# MKL33Z4 register map
Vendor: Freescale Semiconductor, Inc.; Series: Kinetis_L; File version: 1.6
CPU: CM0PLUS r0p0, little endian, no MPU, no FPU, VTOR, 2 interrupt priority bits
Registers are 32-bit, read-write, reset 0x0 unless marked. A register's access mark holds for its fields unless they carry their own. Offsets are from the block's base; [hi:lo] are bit positions; {n}, {i} and the like mark numbered series; 'fields as' and 'values as' point back to an identical list.

## GPIOA — General Purpose Input/Output
Base 0x400FF000; register names take the prefix GPIOA_
0x00 PDOR — Port Data Output Register
  [31:0] PDO — Port Data Output
    0=Logic level 0 is driven on pin, provided pin is configured for general-purpose output; 1=Logic level 1 is driven on pin, provided pin is configured for general-purpose output
0x04 PSOR wo — Port Set Output Register
  [31:0] PTSO — Port Set Output
    0=Corresponding bit in PDORn does not change; 1=Corresponding bit in PDORn is set to logic 1
0x08 PCOR wo — Port Clear Output Register
  [31:0] PTCO — Port Clear Output
    0=Corresponding bit in PDORn does not change; 1=Corresponding bit in PDORn is cleared to logic 0
0x0C PTOR wo — Port Toggle Output Register
  [31:0] PTTO — Port Toggle Output
    0=Corresponding bit in PDORn does not change; 1=Corresponding bit in PDORn is set to the inverse of its existing logic state
0x10 PDIR ro — Port Data Input Register
  [31:0] PDI — Port Data Input
    0=Pin logic level is logic 0, or is not configured for use by digital function; 1=Pin logic level is logic 1
0x14 PDDR — Port Data Direction Register
  [31:0] PDD — Port Data Direction
    0=Pin is configured as general-purpose input, for the GPIO function; 1=Pin is configured as general-purpose output, for the GPIO function

## GPIOB — General Purpose Input/Output
Base 0x400FF040; register names take the prefix GPIOB_
Registers as GPIOA.

## GPIOC — General Purpose Input/Output
Base 0x400FF080; register names take the prefix GPIOC_
Registers as GPIOA.

## GPIOD — General Purpose Input/Output
Base 0x400FF0C0; register names take the prefix GPIOD_
Registers as GPIOA.

## GPIOE — General Purpose Input/Output
Base 0x400FF100; register names take the prefix GPIOE_
Registers as GPIOA.

## MTB — Micro Trace Buffer
Base 0xF0000000; register names take the prefix MTB_
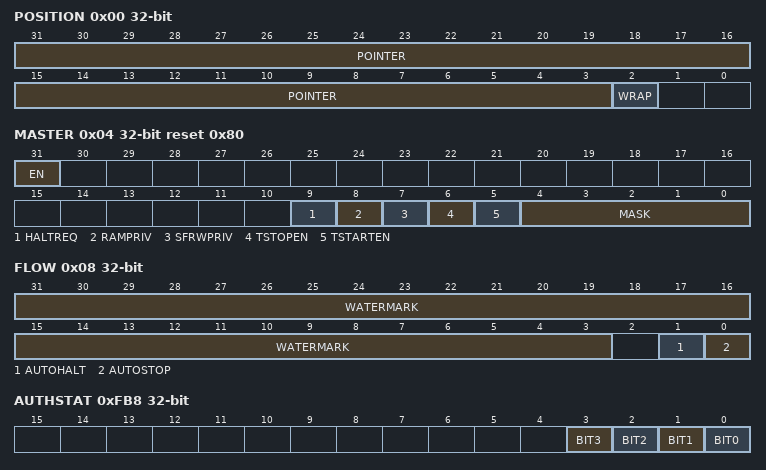
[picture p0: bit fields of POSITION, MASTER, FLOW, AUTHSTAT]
0x00 POSITION (reset mask 0x3) — MTB Position Register
  [31:3] POINTER — Trace Packet Address Pointer[28:0]
  [2] WRAP
0x04 MASTER reset 0x80 (reset mask 0xFFFFFFE0) — MTB Master Register
  [31] EN — Main Trace Enable
  [9] HALTREQ — Halt Request
  [8] RAMPRIV — RAM Privilege
  [7] SFRWPRIV — Special Function Register Write Privilege
  [6] TSTOPEN — Trace Stop Input Enable
  [5] TSTARTEN — Trace Start Input Enable
  [4:0] MASK
0x08 FLOW (reset mask 0x4) — MTB Flow Register
  [31:3] WATERMARK — WATERMARK[28:0]
  [1] AUTOHALT
  [0] AUTOSTOP
0x0C BASE ro reset not defined — MTB Base Register
  [31:0] BASEADDR
0xF00 MODECTRL ro — Integration Mode Control Register
0xFA0 TAGSET ro — Claim TAG Set Register
0xFA4 TAGCLEAR ro — Claim TAG Clear Register
0xFB0 LOCKACCESS ro
  [31:0] LOCKACCESS — Hardwired to 0x0000_0000
0xFB4 LOCKSTAT ro — Lock Status Register
0xFB8 AUTHSTAT ro — Authentication Status Register
  [3] BIT3
  [2] BIT2
  [1] BIT1
  [0] BIT0 — Connected to DBGEN.
0xFBC DEVICEARCH ro reset 0x47700A31 — Device Architecture Register
0xFC8 DEVICECFG ro — Device Configuration Register
0xFCC DEVICETYPID ro reset 0x31 — Device Type Identifier Register
0xFD0 PERIPHID{x} (x=4,5,6,7,0,1,2,3; step 0x4) ro reset not defined — Peripheral ID Register
  [31:0] PERIPHID
{0xFF0+4i} COMPID{i} (i=0..3) ro reset not defined — Component ID Register
  [31:0] COMPID — Component ID

## MTBDWT — MTB data watchpoint and trace
Base 0xF0001000; register names take the prefix MTBDWT_
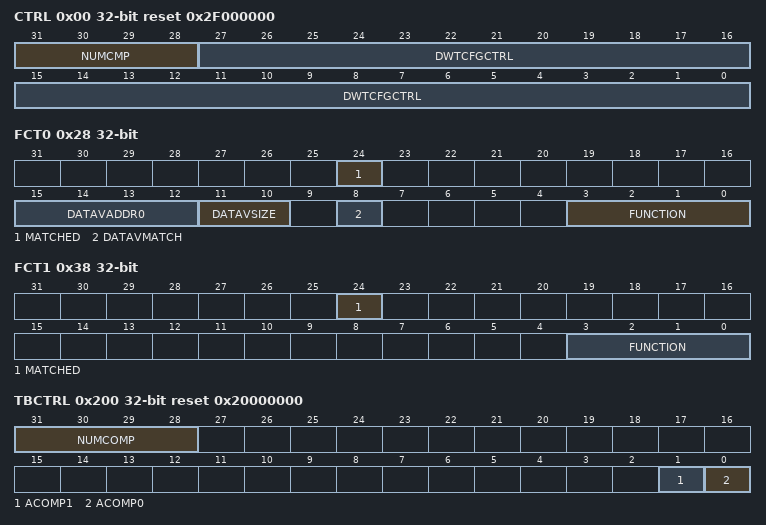
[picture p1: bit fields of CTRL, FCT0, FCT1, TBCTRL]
0x00 CTRL ro reset 0x2F000000 — MTB DWT Control Register
  [31:28] NUMCMP — Number of comparators
  [27:0] DWTCFGCTRL — DWT configuration controls
{0x20+0x10*i} COMP{i} (i=0..1) — MTB_DWT Comparator Register
  [31:0] COMP — Reference value for comparison
{0x24+0x10*i} MASK{i} (i=0..1) — MTB_DWT Comparator Mask Register
  [4:0] MASK
0x28 FCT0 — MTB_DWT Comparator Function Register 0
  [24] MATCHED ro — Comparator match
    0=No match; 1=Match occurred
  [15:12] DATAVADDR0 — Data Value Address 0
  [11:10] DATAVSIZE — Data Value Size
    0=Byte; 1=Halfword; 2=Word; 3=Reserved. Any attempts to use this value results in UNPREDICTABLE behavior.
  [8] DATAVMATCH — Data Value Match
    0=Perform address comparison; 1=Perform data value comparison
  [3:0] FUNCTION
    0=Disabled; 4=Instruction fetch; 5=Data operand read; 6=Data operand write; 7=Data operand (read + write)
0x38 FCT1 — MTB_DWT Comparator Function Register 1
  [24] MATCHED ro — Comparator match
    0=No match; 1=Match occurred
  [3:0] FUNCTION
    values as FCT0.FUNCTION
0x200 TBCTRL reset 0x20000000 — MTB_DWT Trace Buffer Control Register
  [31:28] NUMCOMP ro — Number of Comparators
  [1] ACOMP1 — Action based on Comparator 1 match
    0=Trigger TSTOP based on the assertion of MTBDWT_FCT1[MATCHED]; 1=Trigger TSTART based on the assertion of MTBDWT_FCT1[MATCHED]
  [0] ACOMP0 — Action based on Comparator 0 match
    0=Trigger TSTOP based on the assertion of MTBDWT_FCT0[MATCHED]; 1=Trigger TSTART based on the assertion of MTBDWT_FCT0[MATCHED]
0xFC8 DEVICECFG ro — Device Configuration Register
0xFCC DEVICETYPID ro reset 0x4 — Device Type Identifier Register
0xFD0 PERIPHID{x} (x=4,5,6,7,0,1,2,3; step 0x4) ro reset not defined — Peripheral ID Register
  [31:0] PERIPHID
{0xFF0+4i} COMPID{i} (i=0..3) ro reset not defined — Component ID Register
  [31:0] COMPID — Component ID

## ROM — System ROM
Base 0xF0002000; register names take the prefix ROM_
{0x0+4i} ENTRY{i} (i=0..2) ro reset not defined
  [31:0] ENTRY
0x0C TABLEMARK ro — End of Table Marker Register
  [31:0] MARK
0xFCC SYSACCESS ro reset 0x1 — System Access Register
0xFD0 PERIPHID{x} (x=4,5,6,7,0,1,2,3; step 0x4) ro reset not defined — Peripheral ID Register
  [31:0] PERIPHID
{0xFF0+4i} COMPID{i} (i=0..3) ro reset not defined — Component ID Register
  [31:0] COMPID — Component ID

## MCM — Core Platform Miscellaneous Control Module
Base 0xF0003000; register names take the prefix MCM_
0x08 PLASC 16-bit ro reset 0x7 — Crossbar Switch (AXBS) Slave Configuration
  [7:0] ASC — Each bit in the ASC field indicates whether there is a corresponding connection to the crossbar switch's slave input port.
    0=A bus slave connection to AXBS input port n is absent; 1=A bus slave connection to AXBS input port n is present
0x0A PLAMC 16-bit ro reset 0xD — Crossbar Switch (AXBS) Master Configuration
  [7:0] AMC — Each bit in the AMC field indicates whether there is a corresponding connection to the AXBS master input port.
    0=A bus master connection to AXBS input port n is absent; 1=A bus master connection to AXBS input port n is present
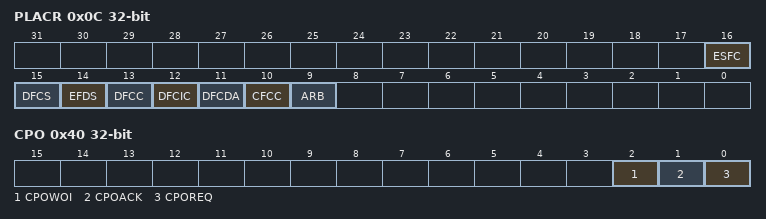
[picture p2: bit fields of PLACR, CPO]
0x0C PLACR — Platform Control Register
  [16] ESFC — Enable Stalling Flash Controller
    0=Disable stalling flash controller when flash is busy; 1=Enable stalling flash controller when flash is busy
  [15] DFCS — Disable Flash Controller Speculation
    0=Enable flash controller speculation; 1=Disable flash controller speculation
  [14] EFDS — Enable Flash Data Speculation
    0=Disable flash data speculation; 1=Enable flash data speculation
  [13] DFCC — Disable Flash Controller Cache
    0=Enable flash controller cache; 1=Disable flash controller cache
  [12] DFCIC — Disable Flash Controller Instruction Caching
    0=Enable flash controller instruction caching; 1=Disable flash controller instruction caching
  [11] DFCDA — Disable Flash Controller Data Caching
    0=Enable flash controller data caching; 1=Disable flash controller data caching
  [10] CFCC wo — Clear Flash Controller Cache
  [9] ARB — Arbitration select
    0=Fixed-priority arbitration for the crossbar masters; 1=Round-robin arbitration for the crossbar masters
0x40 CPO — Compute Operation Control Register
  [2] CPOWOI — Compute Operation Wake-up on Interrupt
    0=No effect; 1=When set, the CPOREQ is cleared on any interrupt or exception vector fetch
  [1] CPOACK ro — Compute Operation Acknowledge
    0=Compute operation entry has not completed or compute operation exit has completed; 1=Compute operation entry has completed or compute operation exit has not completed
  [0] CPOREQ — Compute Operation Request
    0=Request is cleared; 1=Request Compute Operation

## Notices in the file
Redistribution and use in source and binary forms, with or without modification,
are permitted provided that the following conditions are met:
o Redistributions of source code must retain the above copyright notice, this list
of conditions and the following disclaimer.
o Redistributions in binary form must reproduce the above copyright notice, this
list of conditions and the following disclaimer in the documentation and/or
other materials provided with the distribution.
o Neither the name of Freescale Semiconductor, Inc. nor the names of its
contributors may be used to endorse or promote products derived from this
software without specific prior written permission.
THIS SOFTWARE IS PROVIDED BY THE COPYRIGHT HOLDERS AND CONTRIBUTORS "AS IS" AND
ANY EXPRESS OR IMPLIED WARRANTIES, INCLUDING, BUT NOT LIMITED TO, THE IMPLIED
WARRANTIES OF MERCHANTABILITY AND FITNESS FOR A PARTICULAR PURPOSE ARE
DISCLAIMED. IN NO EVENT SHALL THE COPYRIGHT HOLDER OR CONTRIBUTORS BE LIABLE FOR
ANY DIRECT, INDIRECT, INCIDENTAL, SPECIAL, EXEMPLARY, OR CONSEQUENTIAL DAMAGES
(INCLUDING, BUT NOT LIMITED TO, PROCUREMENT OF SUBSTITUTE GOODS OR SERVICES;
LOSS OF USE, DATA, OR PROFITS; OR BUSINESS INTERRUPTION) HOWEVER CAUSED AND ON
ANY THEORY OF LIABILITY, WHETHER IN CONTRACT, STRICT LIABILITY, OR TORT
(INCLUDING NEGLIGENCE OR OTHERWISE) ARISING IN ANY WAY OUT OF THE USE OF THIS
SOFTWARE, EVEN IF ADVISED OF THE POSSIBILITY OF SUCH DAMAGE.
